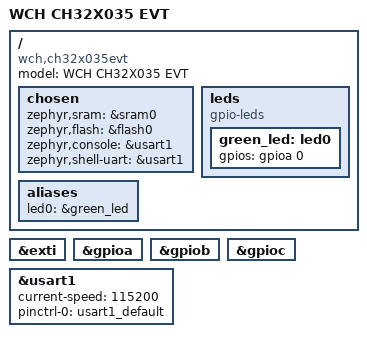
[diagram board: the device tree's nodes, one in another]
/*
 * Copyright (c) 2026 Chen Ren
 * SPDX-License-Identifier: Apache-2.0
 */

/dts-v1/;

#include <wch/ch32x035/ch32x035.dtsi>
#include "ch32x035evt-pinctrl.dtsi"

/ {
	model = "WCH CH32X035 EVT";
	compatible = "wch,ch32x035evt";

	chosen {
		zephyr,sram = &sram0;
		zephyr,flash = &flash0;
		zephyr,console = &usart1;
		zephyr,shell-uart = &usart1;
	};

	leds {
		compatible = "gpio-leds";

		/* PA0 is the user LED on the CH32X035 EVT board, as used by
		 * the WCH GPIO_Toggle example.
		 */
		green_led: led0 {
			gpios = <&gpioa 0 GPIO_ACTIVE_HIGH>;
		};
	};

	aliases {
		led0 = &green_led;
	};
};

&exti {
	status = "okay";
};

&gpioa {
	status = "okay";
};

&gpiob {
	status = "okay";
};

&gpioc {
	status = "okay";
};

&usart1 {
	current-speed = <115200>;
	pinctrl-0 = <&usart1_default>;
	pinctrl-names = "default";
	status = "okay";
};
